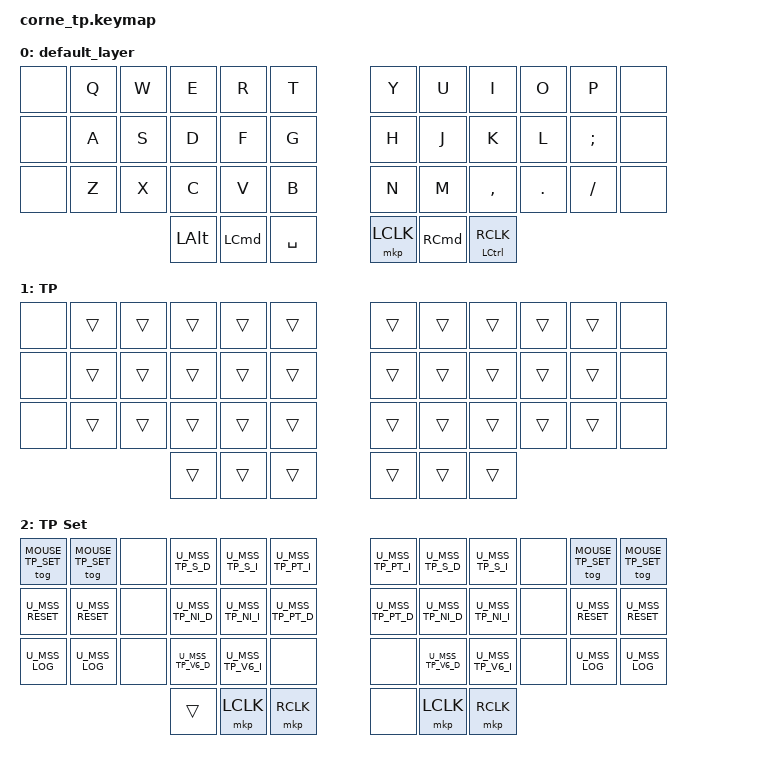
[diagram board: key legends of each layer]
/*
 * Copyright (c) 2020 The ZMK Contributors
 *
 * SPDX-License-Identifier: MIT
 */

#include <behaviors.dtsi>
#include <dt-bindings/zmk/keys.h>
#include <dt-bindings/zmk/bt.h>

// These MUST match the order the layers appear in the `keymap` node below
// (ZMK numbers layers 0,1,2,... by position). If you add/remove/reorder a
// layer, update these too.
#define BASE 0
#define MOUSE_TP 1
#define MOUSE_TP_SET 2

/*
 * Defines to enable/disable features
 *
 * These defines allow us to conditionally enable and disable parts of the keymap config.
 *
 * For example, if we decide to build the firmware without the mouse features, we can
 * disable all the config options that rely on those forks and modules without having
 * to edit the entire keymap file manually every time.
 */

#define HAS_MOUSE_TP

#ifdef HAS_MOUSE_TP
  #include <dt-bindings/zmk/mouse.h>
  #include <behaviors/mouse_keys.dtsi>
  // We store the trackpoint settings in a separate file
  // to make organization a little easier.
  #include "include/mouse_tp.dtsi"
#endif  // HAS_MOUSE_TP



// Adjust layer keys based on enabled features.
//
// This prevents build errors when we build the firmware
// without the TP module.

#ifdef HAS_MOUSE_TP
  #define U_TOG_TP_SET &tog MOUSE_TP_SET
#else
  #define U_TOG_TP_SET &none
#endif  // HAS_MOUSE_TP

/ {

  chosen {
    zmk,battery = &vbatt;
  };

  vbatt: vbatt {
    compatible = "zmk,battery-nrf-vddh";
    label = "VBATT";
  };

  behaviors {
    // tap = mouse key, hold = normal key
    hold_mkp: hold_mkp {
      compatible = "zmk,behavior-hold-tap";
      #binding-cells = <2>;
      tapping-term-ms = <200>;
      flavor = "tap-preferred";
      bindings = <&kp>, <&mkp>;   // <hold>, <tap>
    };
  };

  combos {
    compatible = "zmk,combos";
    combo_tab { timeout-ms = <30>; key-positions = <14 15>; bindings = <&kp TAB>; };
    combo_del { timeout-ms = <30>; key-positions = <15 16>; bindings = <&kp BSPC>; };
    combo_esc { timeout-ms = <30>; key-positions = <19 20>; bindings = <&kp ESC>; };
    combo_ret { timeout-ms = <30>; key-positions = <20 21>; bindings = <&kp RET>; };
  };

  keymap {
    compatible = "zmk,keymap";

    default_layer {
      bindings = <
          //   |----1----|----2----|----3----|----4----|----5----|    |----6----|----7----|----8----|----9----|----10---|
          &none   &kp Q     &kp W     &kp E     &kp R     &kp T          &kp Y     &kp U     &kp I     &kp O     &kp P     &none
          //   |----13---|----14---|----15---|----16---|----17---|    |----18---|----19---|----20---|----21---|----22---|
          &none   &kp A     &kp S     &kp D     &kp F     &kp G          &kp H     &kp J     &kp K     &kp L    &kp SEMI   &none
          //   |----25---|----26---|----27---|----28---|----29---|    |----30---|----31---|----32---|----33---|----34---|
          &none   &kp Z     &kp X     &kp C     &kp V     &kp B          &kp N     &kp M   &kp COMMA  &kp DOT  &kp FSLH    &none
          //                       |---------|---------|---------|    |---------|---------|---------|
                                    &kp LALT  &kp LCMD  &kp SPACE      &mkp LCLK &kp RCMD  &hold_mkp LCTRL RCLK
      >;
    };

#ifdef HAS_MOUSE_TP

    // Automatically activated when the mouse or trackpoint moves.
    // Configured in `include/mouse_tp.dtsi`.
    MouseTP_layer {
      display-name = "TP";
      bindings = <
          //   |----1----|----2----|----3----|----4----|----5----|    |----6----|----7----|----8----|----9----|----10---|
          &none  &trans     &trans    &trans    &trans    &trans         &trans    &trans    &trans    &trans    &trans    &none
          //   |----13---|----14---|----15---|----16---|----17---|    |----18---|----19---|----20---|----21---|----22---|
          &none  &trans     &trans    &trans    &trans    &trans         &trans    &trans    &trans    &trans    &trans    &none
          //   |----25---|----26---|----27---|----28---|----29---|    |----30---|----31---|----32---|----33---|----34---|
          &none  &trans     &trans    &trans    &trans    &trans         &trans    &trans    &trans    &trans    &trans    &none
          //                       |---------|---------|---------|    |---------|---------|---------|
                                      &trans    &trans    &trans         &trans    &trans    &trans
      >;
    };

    // You can find the defines for the actual key press behaviors in `include/mouse_tp.dtsi`.
    MouseSettings_layer {
      display-name = "TP Set";
      bindings = <
// ╭────────────────────────┬────────────────────────┬────────────────────────┬────────────────────────┬────────────────────────┬────────────────────────╮    ╭────────────────────────┬────────────────────────┬────────────────────────┬────────────────────────┬────────────────────────┬────────────────────────╮
     U_TOG_TP_SET             U_TOG_TP_SET             &none                    U_MSS_TP_S_D             U_MSS_TP_S_I             U_MSS_TP_PT_I                 U_MSS_TP_PT_I            U_MSS_TP_S_D             U_MSS_TP_S_I             &none                    U_TOG_TP_SET              U_TOG_TP_SET
// ├────────────────────────┼────────────────────────┼────────────────────────┼────────────────────────┼────────────────────────┼────────────────────────┤    ├────────────────────────┼────────────────────────┼────────────────────────┼────────────────────────┼────────────────────────┼────────────────────────┤
     U_MSS_RESET              U_MSS_RESET              &none                    U_MSS_TP_NI_D            U_MSS_TP_NI_I            U_MSS_TP_PT_D                 U_MSS_TP_PT_D            U_MSS_TP_NI_D            U_MSS_TP_NI_I            &none                    U_MSS_RESET               U_MSS_RESET
// ├────────────────────────┼────────────────────────┼────────────────────────┼────────────────────────┼────────────────────────┼────────────────────────┤    ├────────────────────────┼────────────────────────┼────────────────────────┼────────────────────────┼────────────────────────┼────────────────────────┤
     U_MSS_LOG                U_MSS_LOG                &none                    U_MSS_TP_V6_D            U_MSS_TP_V6_I            &none                         &none                    U_MSS_TP_V6_D            U_MSS_TP_V6_I            &none                    U_MSS_LOG                 U_MSS_LOG
// ╰────────────────────────┴────────────────────────┴────────────────────────┴────────────────────────┼────────────────────────┼────────────────────────┤    ├────────────────────────┼────────────────────────┼────────────────────────┼────────────────────────┴────────────────────────┼────────────────────────╯
                                                                                &trans                   &mkp LCLK                &mkp RCLK                     &none                    &mkp LCLK                &mkp RCLK
//                                                                            ╰────────────────────────┴────────────────────────┴────────────────────────╯    ╰────────────────────────┴────────────────────────┴────────────────────────╯
      >;
    };

#endif
  };
};
